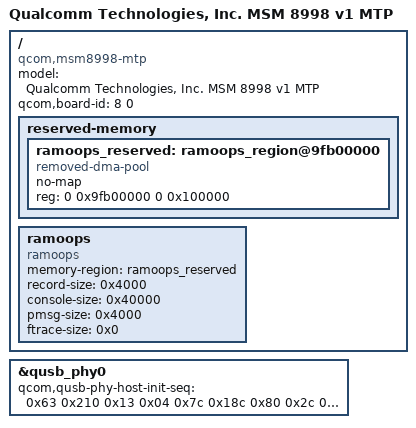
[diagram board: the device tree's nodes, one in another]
/* Copyright (c) 2016-2017, The Linux Foundation. All rights reserved.
 *
 * This program is free software; you can redistribute it and/or modify
 * it under the terms of the GNU General Public License version 2 and
 * only version 2 as published by the Free Software Foundation.
 *
 * This program is distributed in the hope that it will be useful,
 * but WITHOUT ANY WARRANTY; without even the implied warranty of
 * MERCHANTABILITY or FITNESS FOR A PARTICULAR PURPOSE.  See the
 * GNU General Public License for more details.
 */


/dts-v1/;

#include "msm8998.dtsi"
#include "msm8998-mdss-panels.dtsi"
#include "msm8998-mtp.dtsi"

/ {
	model = "Qualcomm Technologies, Inc. MSM 8998 v1 MTP";
	compatible = "qcom,msm8998-mtp", "qcom,msm8998", "qcom,mtp";
	qcom,board-id = <8 0>;
};

&qusb_phy0 {
	qcom,qusb-phy-host-init-seq =
			/* value reg_offsets> */
				<0x63 0x210
				0x13 0x04
				0x7c 0x18c
				0x80 0x2c
				0x0a 0x184
				0x8c 0x21c
				0x05 0x23c
				0x03 0x240
				0xff 0x218
				0x62 0x210>;
};

/*
 * ramoops: Persistent store for kernel panic/oops/console logs.
 * Located at 0x9fb00000 (1MB), with a 1MB guard band after splash_region.
 * This region is chosen because:
 * 1. It's after all SoC-reserved areas in msm8998.dtsi
 * 2. 1MB guard band (0x9fa00000-0x9fb00000) protects against display DMA prefetch
 * 3. Within RAM range for both 6GB and 8GB configurations
 * 4. 1MB-aligned and unlikely to conflict with vendor-specific allocations
 *
 * Memory layout:
 * - console-size: 256KB (console log buffer)
 * - pmsg-size: 16KB (user-space messages via /dev/pmsg0)
 * - record-size: 16KB (per panic/oops dump)
 * - ftrace-size: 0 (disabled)
 * Total: 1MB
 *
 * Note: Data persistence across reboot depends on:
 * - Bootloader not clearing this region
 * - No DMA/hardware access during normal operation
 * - Proper no-map attribute preventing kernel mapping
 */
/ {
	reserved-memory {
		ramoops_reserved: ramoops_region@9fb00000 {
			compatible = "removed-dma-pool";
			no-map;
			reg = <0 0x9fb00000 0 0x100000>;
		};
	};

	ramoops {
		compatible = "ramoops";
		memory-region = <&ramoops_reserved>;
		record-size = <0x4000>;
		console-size = <0x40000>;
		pmsg-size = <0x4000>;
		ftrace-size = <0x0>;
	};
};

#include "nubia/NX595J/head.dtsi"
